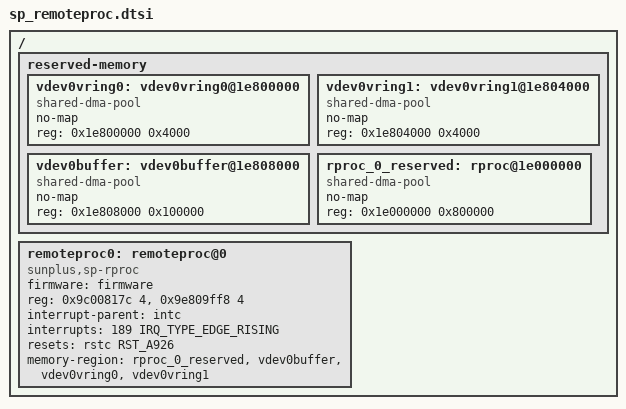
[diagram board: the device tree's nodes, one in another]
/ {
	reserved-memory {
		#address-cells = <1>;
		#size-cells = <1>;
		ranges;
		vdev0vring0: vdev0vring0@1e800000 {
			no-map;
			compatible = "shared-dma-pool";
			reg = <0x1e800000 0x4000>;
		};
		vdev0vring1: vdev0vring1@1e804000 {
			no-map;
			compatible = "shared-dma-pool";
			reg = <0x1e804000 0x4000>;
		};
		vdev0buffer: vdev0buffer@1e808000 {
			no-map;
			compatible = "shared-dma-pool";
			reg = <0x1e808000 0x100000>;
		};
		rproc_0_reserved: rproc@1e000000 {
			no-map;
			compatible = "shared-dma-pool";
			reg = <0x1e000000 0x800000>;
		};
	};

	remoteproc0: remoteproc@0 {
		compatible = "sunplus,sp-rproc";
		firmware = "firmware";
		reg = <0x9c00817c 4>, /* mbox G258.31 */
			  <0x9e809ff8 4>; /* boot A926 */
		interrupt-parent = <&intc>;
		interrupts = <189 IRQ_TYPE_EDGE_RISING>; /* ACHIPCPU0_DIRECT_INT7 */
		resets = <&rstc RST_A926>;
		memory-region = <&rproc_0_reserved>, <&vdev0buffer>, <&vdev0vring0>, <&vdev0vring1>;
	};
};
